# ATtiny416auto device description
Architecture: AVR8X; Family: AVR TINY
Registers are 8-bit, read-write, no defined reset value unless marked. A register's access mark holds for its fields unless they carry their own. Offsets are from the block's base; [hi:lo] are bit positions; {n}, {i} and the like mark numbered series.

## AC — Analog Comparator
Instances: AC0 0x0670
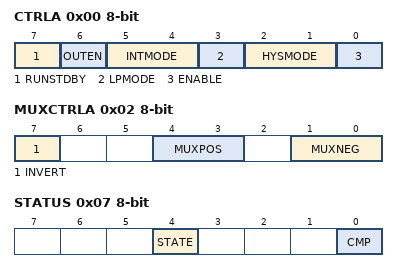
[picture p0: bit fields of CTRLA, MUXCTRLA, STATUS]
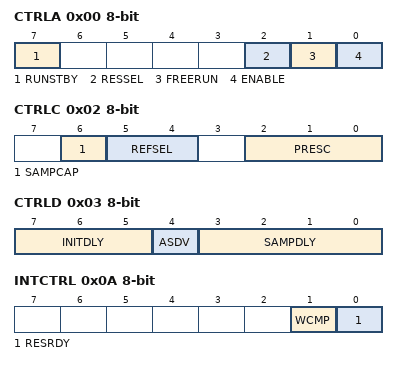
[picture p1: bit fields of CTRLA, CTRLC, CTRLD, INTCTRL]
0x00 CTRLA — Control A
  [7] RUNSTDBY — Run in Standby Mode
  [6] OUTEN — Output Buffer Enable
  [5:4] INTMODE — Interrupt Mode
    0=BOTHEDGE (Any Edge); 2=NEGEDGE (Negative Edge); 3=POSEDGE (Positive Edge)
  [3] LPMODE — Low Power Mode
    0=DIS (Low power mode disabled); 1=EN (Low power mode enabled)
  [2:1] HYSMODE — Hysteresis Mode
    0=OFF (No hysteresis); 1=10mV hysteresis; 2=25mV hysteresis; 3=50mV hysteresis
  [0] ENABLE
0x02 MUXCTRLA — Mux Control A
  [7] INVERT — Invert AC Output
  [4:3] MUXPOS — Positive Input MUX Selection
    0=PIN0 (Positive Pin 0); 1=PIN1 (Positive Pin 1)
  [1:0] MUXNEG — Negative Input MUX Selection
    0=PIN0 (Negative Pin 0); 1=PIN1 (Negative Pin 1); 2=VREF (Voltage Reference); 3=DAC (DAC output)
0x06 INTCTRL — Interrupt Control
  [0] CMP — Analog Comparator 0 Interrupt Enable
0x07 STATUS
  [4] STATE ro — Analog Comparator State
  [0] CMP — Analog Comparator Interrupt Flag

## ADC — Analog to Digital Converter
Instances: ADC0 0x0600
0x00 CTRLA — Control A
  [7] RUNSTBY — Run standby mode
  [2] RESSEL — ADC Resolution
    0=10BIT (10-bit mode); 1=8BIT (8-bit mode)
  [1] FREERUN — ADC Freerun mode
  [0] ENABLE — ADC Enable
0x01 CTRLB — Control B
  [2:0] SAMPNUM — Accumulation Samples
    0=ACC1 (1 ADC sample); 1=ACC2 (Accumulate 2 samples); 2=ACC4 (Accumulate 4 samples); 3=ACC8 (Accumulate 8 samples); 4=ACC16 (Accumulate 16 samples); 5=ACC32 (Accumulate 32 samples); 6=ACC64 (Accumulate 64 samples)
0x02 CTRLC — Control C
  [6] SAMPCAP — Sample Capacitance Selection
  [5:4] REFSEL — Reference Selection
    0=INTREF (Internal reference); 1=VDDREF
  [2:0] PRESC — Clock Pre-scaler
    0=DIV2 (CLK_PER divided by 2); 1=DIV4 (CLK_PER divided by 4); 2=DIV8 (CLK_PER divided by 8); 3=DIV16 (CLK_PER divided by 16); 4=DIV32 (CLK_PER divided by 32); 5=DIV64 (CLK_PER divided by 64); 6=DIV128 (CLK_PER divided by 128); 7=DIV256 (CLK_PER divided by 256)
0x03 CTRLD — Control D
  [7:5] INITDLY — Initial Delay Selection
    0=DLY0 (Delay 0 CLK_ADC cycles); 1=DLY16 (Delay 16 CLK_ADC cycles); 2=DLY32 (Delay 32 CLK_ADC cycles); 3=DLY64 (Delay 64 CLK_ADC cycles); 4=DLY128 (Delay 128 CLK_ADC cycles); 5=DLY256 (Delay 256 CLK_ADC cycles)
  [4] ASDV — Automatic Sampling Delay Variation
    0=ASVOFF (The Automatic Sampling Delay Variation is disabled); 1=ASVON (The Automatic Sampling Delay Variation is enabled)
  [3:0] SAMPDLY — Sampling Delay Selection
0x04 CTRLE — Control E
  [2:0] WINCM — Window Comparator Mode
    0=NONE (No Window Comparison); 1=BELOW (Below Window); 2=ABOVE (Above Window); 3=INSIDE (Inside Window); 4=OUTSIDE (Outside Window)
0x05 SAMPCTRL — Sample Control
  [4:0] SAMPLEN — Sample lenght
0x06 MUXPOS — Positive mux input
  [4:0] MUXPOS — Analog Channel Selection Bits
    {v}=AIN{v} (ADC input pin {v}) (v=0..11); 28=DAC0; 29=INTREF (Internal Ref); 30=TEMPSENSE (Temp sensor); 31=GND
0x08 COMMAND
  [0] STCONV — Start Conversion Operation
0x09 EVCTRL — Event Control
  [0] STARTEI — Start Event Input Enable
0x0A INTCTRL — Interrupt Control
  [1] WCMP — Window Comparator Interrupt Enable
  [0] RESRDY — Result Ready Interrupt Enable
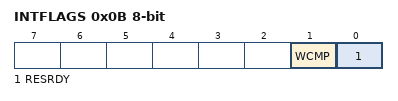
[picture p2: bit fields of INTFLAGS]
0x0B INTFLAGS — Interrupt Flags
  [1] WCMP — Window Comparator Flag
  [0] RESRDY — Result Ready Flag
0x0C DBGCTRL — Debug Control
  [0] DBGRUN — Debug run
0x0D TEMP — Temporary Data
  [7:0] TEMP — Temporary
0x10 RES 16-bit ro — ADC Accumulator Result
0x12 WINLT 16-bit — Window comparator low threshold
0x14 WINHT 16-bit — Window comparator high threshold
0x16 CALIB — Calibration
  [0] DUTYCYC — Duty Cycle
    0=DUTY50 (50% Duty cycle); 1=DUTY25 (25% Duty cycle)

## BOD — Bod interface
Instances: BOD 0x0080
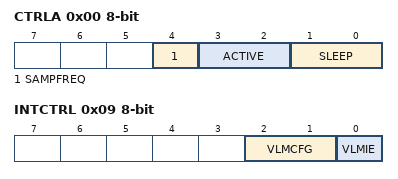
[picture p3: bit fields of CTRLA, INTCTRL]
0x00 CTRLA — Control A
  [4] SAMPFREQ ro — Sample frequency
    0=1KHZ (1kHz sampling); 1=125Hz sampling
  [3:2] ACTIVE ro — Operation in active mode
    0=DIS (Disabled); 1=ENABLED; 2=SAMPLED; 3=ENWAKE (Enabled with wakeup halt)
  [1:0] SLEEP — Operation in sleep mode
    0=DIS (Disabled); 1=ENABLED; 2=SAMPLED
0x01 CTRLB — Control B
  [2:0] LVL ro — Bod level
    0=BODLEVEL0 (1.8 V); 1=BODLEVEL1 (2.1 V); 2=BODLEVEL2 (2.6 V); 3=BODLEVEL3 (2.9 V); 4=BODLEVEL4 (3.3 V); 5=BODLEVEL5 (3.7 V); 6=BODLEVEL6 (4.0 V); 7=BODLEVEL7 (4.2 V)
0x08 VLMCTRLA — Voltage level monitor Control
  [1:0] VLMLVL — voltage level monitor level
    0=5ABOVE (VLM threshold 5% above BOD level); 1=15ABOVE (VLM threshold 15% above BOD level); 2=25ABOVE (VLM threshold 25% above BOD level)
0x09 INTCTRL — Voltage level monitor interrupt Control
  [2:1] VLMCFG — Configuration
    0=BELOW (Interrupt when supply goes below VLM level); 1=ABOVE (Interrupt when supply goes above VLM level); 2=CROSS (Interrupt when supply crosses VLM level)
  [0] VLMIE — voltage level monitor interrrupt enable
0x0A INTFLAGS — Voltage level monitor interrupt Flags
  [0] VLMIF — Voltage level monitor interrupt flag
0x0B STATUS — Voltage level monitor status
  [0] VLMS ro
